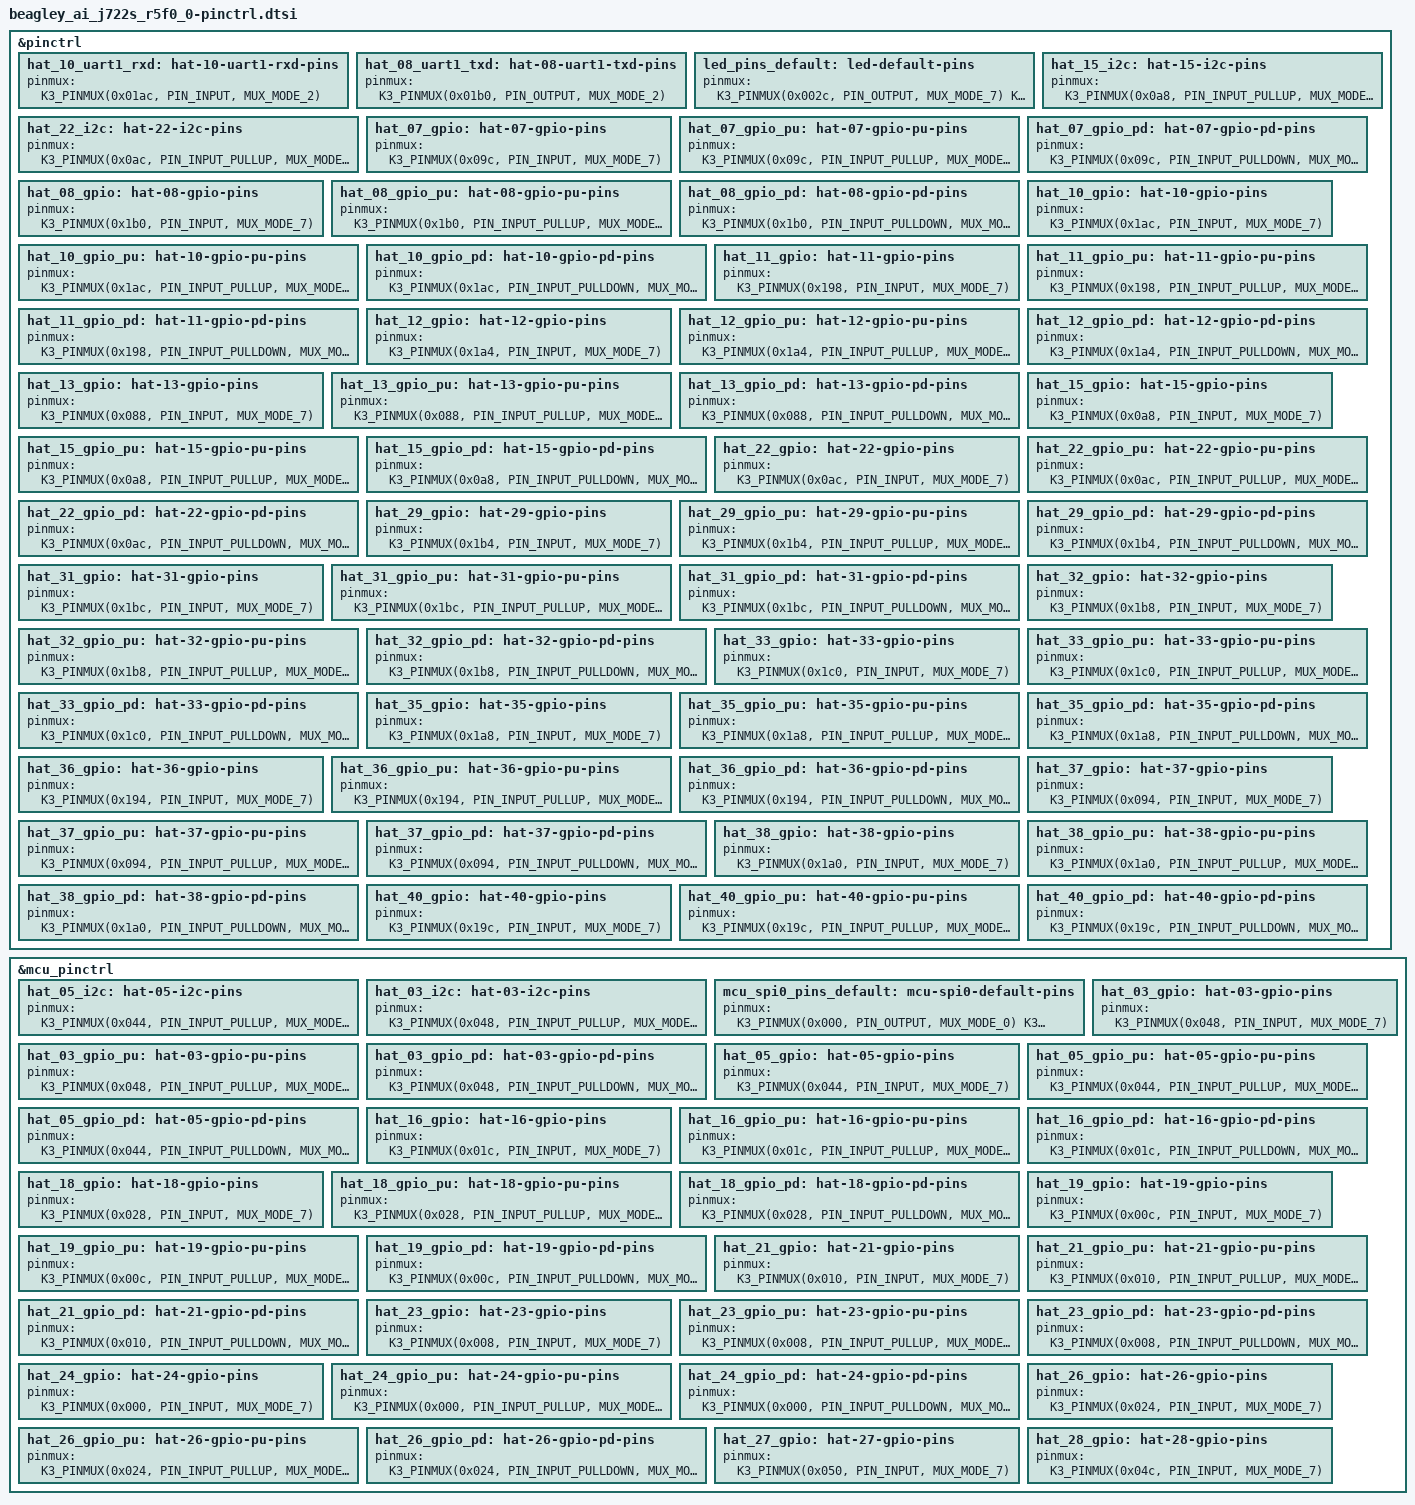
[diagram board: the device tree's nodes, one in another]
/*
 * Copyright (c) 2024 Texas Instruments Incorporated
 *	Andrew Davis <afd@ti.com>
 *
 * SPDX-License-Identifier: Apache-2.0
 */

#include <zephyr/dt-bindings/pinctrl/ti-k3-pinctrl.h>

&pinctrl {
	hat_10_uart1_rxd: hat-10-uart1-rxd-pins {
		/* HAT pin 10, GPIO15, UART RX */
		pinmux = <K3_PINMUX(0x01ac, PIN_INPUT, MUX_MODE_2)>;
	};

	hat_08_uart1_txd: hat-08-uart1-txd-pins {
		/* HAT pin 8, GPIO14, UART TX */
		pinmux = <K3_PINMUX(0x01b0, PIN_OUTPUT, MUX_MODE_2)>;
	};

	led_pins_default: led-default-pins {
		pinmux = <
			  /* (K26) OSPI0_CSn0.GPIO0_11 */
			  K3_PINMUX(0x002c, PIN_OUTPUT, MUX_MODE_7)
			  /* (K23) OSPI0_CSn1.GPIO0_12 */
			  K3_PINMUX(0x0030, PIN_OUTPUT, MUX_MODE_7)>;
	};

	/* Optional HAT I2C4 (https://pinout.beagleboard.io/pinout/i2c) */
	hat_15_i2c: hat-15-i2c-pins {
		/* HAT pin 15, GPIO22, I2C4 clock */
		pinmux = <K3_PINMUX(0x0a8, PIN_INPUT_PULLUP, MUX_MODE_1)>;
	};

	hat_22_i2c: hat-22-i2c-pins {
		/* HAT pin 22, GPIO25, I2C4 data */
		pinmux = <K3_PINMUX(0x0ac, PIN_INPUT_PULLUP, MUX_MODE_1)>;
	};

	hat_07_gpio: hat-07-gpio-pins {
		/* (W26) GPMC0_WAIT1.GPIO0_38 */
		pinmux = <K3_PINMUX(0x09c, PIN_INPUT, MUX_MODE_7)>;
	};

	hat_07_gpio_pu: hat-07-gpio-pu-pins {
		/* (W26) GPMC0_WAIT1.GPIO0_38 */
		pinmux = <K3_PINMUX(0x09c, PIN_INPUT_PULLUP, MUX_MODE_7)>;
	};

	hat_07_gpio_pd: hat-07-gpio-pd-pins {
		/* (W26) GPMC0_WAIT1.GPIO0_38 */
		pinmux = <K3_PINMUX(0x09c, PIN_INPUT_PULLDOWN, MUX_MODE_7)>;
	};

	hat_08_gpio: hat-08-gpio-pins {
		/* (F24) MCASP0_ACLKR.GPIO1_14 */
		pinmux = <K3_PINMUX(0x1b0, PIN_INPUT, MUX_MODE_7)>;
	};

	hat_08_gpio_pu: hat-08-gpio-pu-pins {
		/* (F24) MCASP0_ACLKR.GPIO1_14 */
		pinmux = <K3_PINMUX(0x1b0, PIN_INPUT_PULLUP, MUX_MODE_7)>;
	};

	hat_08_gpio_pd: hat-08-gpio-pd-pins {
		/* (F24) MCASP0_ACLKR.GPIO1_14 */
		pinmux = <K3_PINMUX(0x1b0, PIN_INPUT_PULLDOWN, MUX_MODE_7)>;
	};

	hat_10_gpio: hat-10-gpio-pins {
		/* (C27) MCASP0_AFSR.GPIO1_13 */
		pinmux = <K3_PINMUX(0x1ac, PIN_INPUT, MUX_MODE_7)>;
	};

	hat_10_gpio_pu: hat-10-gpio-pu-pins {
		/* (C27) MCASP0_AFSR.GPIO1_13 */
		pinmux = <K3_PINMUX(0x1ac, PIN_INPUT_PULLUP, MUX_MODE_7)>;
	};

	hat_10_gpio_pd: hat-10-gpio-pd-pins {
		/* (C27) MCASP0_AFSR.GPIO1_13 */
		pinmux = <K3_PINMUX(0x1ac, PIN_INPUT_PULLDOWN, MUX_MODE_7)>;
	};

	hat_11_gpio: hat-11-gpio-pins {
		/* (A26) MCASP0_AXR2.GPIO1_8 */
		pinmux = <K3_PINMUX(0x198, PIN_INPUT, MUX_MODE_7)>;
	};

	hat_11_gpio_pu: hat-11-gpio-pu-pins {
		/* (A26) MCASP0_AXR2.GPIO1_8 */
		pinmux = <K3_PINMUX(0x198, PIN_INPUT_PULLUP, MUX_MODE_7)>;
	};

	hat_11_gpio_pd: hat-11-gpio-pd-pins {
		/* (A26) MCASP0_AXR2.GPIO1_8 */
		pinmux = <K3_PINMUX(0x198, PIN_INPUT_PULLDOWN, MUX_MODE_7)>;
	};

	hat_12_gpio: hat-12-gpio-pins {
		/* (D25) MCASP0_ACLKX.GPIO1_11 */
		pinmux = <K3_PINMUX(0x1a4, PIN_INPUT, MUX_MODE_7)>;
	};

	hat_12_gpio_pu: hat-12-gpio-pu-pins {
		/* (D25) MCASP0_ACLKX.GPIO1_11 */
		pinmux = <K3_PINMUX(0x1a4, PIN_INPUT_PULLUP, MUX_MODE_7)>;
	};

	hat_12_gpio_pd: hat-12-gpio-pd-pins {
		/* (D25) MCASP0_ACLKX.GPIO1_11 */
		pinmux = <K3_PINMUX(0x1a4, PIN_INPUT_PULLDOWN, MUX_MODE_7)>;
	};

	hat_13_gpio: hat-13-gpio-pins {
		/* (N22) GPMC0_OEn_REn.GPIO0_33 */
		pinmux = <K3_PINMUX(0x088, PIN_INPUT, MUX_MODE_7)>;
	};

	hat_13_gpio_pu: hat-13-gpio-pu-pins {
		/* (N22) GPMC0_OEn_REn.GPIO0_33 */
		pinmux = <K3_PINMUX(0x088, PIN_INPUT_PULLUP, MUX_MODE_7)>;
	};

	hat_13_gpio_pd: hat-13-gpio-pd-pins {
		/* (N22) GPMC0_OEn_REn.GPIO0_33 */
		pinmux = <K3_PINMUX(0x088, PIN_INPUT_PULLDOWN, MUX_MODE_7)>;
	};

	hat_15_gpio: hat-15-gpio-pins {
		/* (R27) GPMC0_CSn0.GPIO0_41 */
		pinmux = <K3_PINMUX(0x0a8, PIN_INPUT, MUX_MODE_7)>;
	};

	hat_15_gpio_pu: hat-15-gpio-pu-pins {
		/* (R27) GPMC0_CSn0.GPIO0_41 */
		pinmux = <K3_PINMUX(0x0a8, PIN_INPUT_PULLUP, MUX_MODE_7)>;
	};

	hat_15_gpio_pd: hat-15-gpio-pd-pins {
		/* (R27) GPMC0_CSn0.GPIO0_41 */
		pinmux = <K3_PINMUX(0x0a8, PIN_INPUT_PULLDOWN, MUX_MODE_7)>;
	};

	hat_22_gpio: hat-22-gpio-pins {
		/* (P21) GPMC0_CSn1.GPIO0_42 */
		pinmux = <K3_PINMUX(0x0ac, PIN_INPUT, MUX_MODE_7)>;
	};

	hat_22_gpio_pu: hat-22-gpio-pu-pins {
		/* (P21) GPMC0_CSn1.GPIO0_42 */
		pinmux = <K3_PINMUX(0x0ac, PIN_INPUT_PULLUP, MUX_MODE_7)>;
	};

	hat_22_gpio_pd: hat-22-gpio-pd-pins {
		/* (P21) GPMC0_CSn1.GPIO0_42 */
		pinmux = <K3_PINMUX(0x0ac, PIN_INPUT_PULLDOWN, MUX_MODE_7)>;
	};

	hat_29_gpio: hat-29-gpio-pins {
		/* (B20) SPI0_CS0.GPIO1_15 */
		pinmux = <K3_PINMUX(0x1b4, PIN_INPUT, MUX_MODE_7)>;
	};

	hat_29_gpio_pu: hat-29-gpio-pu-pins {
		/* (B20) SPI0_CS0.GPIO1_15 */
		pinmux = <K3_PINMUX(0x1b4, PIN_INPUT_PULLUP, MUX_MODE_7)>;
	};

	hat_29_gpio_pd: hat-29-gpio-pd-pins {
		/* (B20) SPI0_CS0.GPIO1_15 */
		pinmux = <K3_PINMUX(0x1b4, PIN_INPUT_PULLDOWN, MUX_MODE_7)>;
	};

	hat_31_gpio: hat-31-gpio-pins {
		/* (D20) SPI0_CLK.GPIO1_17 */
		pinmux = <K3_PINMUX(0x1bc, PIN_INPUT, MUX_MODE_7)>;
	};

	hat_31_gpio_pu: hat-31-gpio-pu-pins {
		/* (D20) SPI0_CLK.GPIO1_17 */
		pinmux = <K3_PINMUX(0x1bc, PIN_INPUT_PULLUP, MUX_MODE_7)>;
	};

	hat_31_gpio_pd: hat-31-gpio-pd-pins {
		/* (D20) SPI0_CLK.GPIO1_17 */
		pinmux = <K3_PINMUX(0x1bc, PIN_INPUT_PULLDOWN, MUX_MODE_7)>;
	};

	hat_32_gpio: hat-32-gpio-pins {
		/* (C20) SPI0_CS1.GPIO1_16 */
		pinmux = <K3_PINMUX(0x1b8, PIN_INPUT, MUX_MODE_7)>;
	};

	hat_32_gpio_pu: hat-32-gpio-pu-pins {
		/* (C20) SPI0_CS1.GPIO1_16 */
		pinmux = <K3_PINMUX(0x1b8, PIN_INPUT_PULLUP, MUX_MODE_7)>;
	};

	hat_32_gpio_pd: hat-32-gpio-pd-pins {
		/* (C20) SPI0_CS1.GPIO1_16 */
		pinmux = <K3_PINMUX(0x1b8, PIN_INPUT_PULLDOWN, MUX_MODE_7)>;
	};

	hat_33_gpio: hat-33-gpio-pins {
		/* (E19) SPI0_D0.GPIO1_18 */
		pinmux = <K3_PINMUX(0x1c0, PIN_INPUT, MUX_MODE_7)>;
	};

	hat_33_gpio_pu: hat-33-gpio-pu-pins {
		/* (E19) SPI0_D0.GPIO1_18 */
		pinmux = <K3_PINMUX(0x1c0, PIN_INPUT_PULLUP, MUX_MODE_7)>;
	};

	hat_33_gpio_pd: hat-33-gpio-pd-pins {
		/* (E19) SPI0_D0.GPIO1_18 */
		pinmux = <K3_PINMUX(0x1c0, PIN_INPUT_PULLDOWN, MUX_MODE_7)>;
	};

	hat_35_gpio: hat-35-gpio-pins {
		/* (C26) MCASP0_AFSX.GPIO1_12 */
		pinmux = <K3_PINMUX(0x1a8, PIN_INPUT, MUX_MODE_7)>;
	};

	hat_35_gpio_pu: hat-35-gpio-pu-pins {
		/* (C26) MCASP0_AFSX.GPIO1_12 */
		pinmux = <K3_PINMUX(0x1a8, PIN_INPUT_PULLUP, MUX_MODE_7)>;
	};

	hat_35_gpio_pd: hat-35-gpio-pd-pins {
		/* (C26) MCASP0_AFSX.GPIO1_12 */
		pinmux = <K3_PINMUX(0x1a8, PIN_INPUT_PULLDOWN, MUX_MODE_7)>;
	};

	hat_36_gpio: hat-36-gpio-pins {
		/* (A25) MCASP0_AXR3.GPIO1_7 */
		pinmux = <K3_PINMUX(0x194, PIN_INPUT, MUX_MODE_7)>;
	};

	hat_36_gpio_pu: hat-36-gpio-pu-pins {
		/* (A25) MCASP0_AXR3.GPIO1_7 */
		pinmux = <K3_PINMUX(0x194, PIN_INPUT_PULLUP, MUX_MODE_7)>;
	};

	hat_36_gpio_pd: hat-36-gpio-pd-pins {
		/* (A25) MCASP0_AXR3.GPIO1_7 */
		pinmux = <K3_PINMUX(0x194, PIN_INPUT_PULLDOWN, MUX_MODE_7)>;
	};

	hat_37_gpio: hat-37-gpio-pins {
		/* (P26) GPMC0_BE1n.GPIO0_36 */
		pinmux = <K3_PINMUX(0x094, PIN_INPUT, MUX_MODE_7)>;
	};

	hat_37_gpio_pu: hat-37-gpio-pu-pins {
		/* (P26) GPMC0_BE1n.GPIO0_36 */
		pinmux = <K3_PINMUX(0x094, PIN_INPUT_PULLUP, MUX_MODE_7)>;
	};

	hat_37_gpio_pd: hat-37-gpio-pd-pins {
		/* (P26) GPMC0_BE1n.GPIO0_36 */
		pinmux = <K3_PINMUX(0x094, PIN_INPUT_PULLDOWN, MUX_MODE_7)>;
	};

	hat_38_gpio: hat-38-gpio-pins {
		/* (F23) MCASP0_AXR0.GPIO1_10 */
		pinmux = <K3_PINMUX(0x1a0, PIN_INPUT, MUX_MODE_7)>;
	};

	hat_38_gpio_pu: hat-38-gpio-pu-pins {
		/* (F23) MCASP0_AXR0.GPIO1_10 */
		pinmux = <K3_PINMUX(0x1a0, PIN_INPUT_PULLUP, MUX_MODE_7)>;
	};

	hat_38_gpio_pd: hat-38-gpio-pd-pins {
		/* (F23) MCASP0_AXR0.GPIO1_10 */
		pinmux = <K3_PINMUX(0x1a0, PIN_INPUT_PULLDOWN, MUX_MODE_7)>;
	};

	hat_40_gpio: hat-40-gpio-pins {
		/* (B25) MCASP0_AXR1.GPIO1_9 */
		pinmux = <K3_PINMUX(0x19c, PIN_INPUT, MUX_MODE_7)>;
	};

	hat_40_gpio_pu: hat-40-gpio-pu-pins {
		/* (B25) MCASP0_AXR1.GPIO1_9 */
		pinmux = <K3_PINMUX(0x19c, PIN_INPUT_PULLUP, MUX_MODE_7)>;
	};

	hat_40_gpio_pd: hat-40-gpio-pd-pins {
		/* (B25) MCASP0_AXR1.GPIO1_9 */
		pinmux = <K3_PINMUX(0x19c, PIN_INPUT_PULLDOWN, MUX_MODE_7)>;
	};
};

&mcu_pinctrl {
	/*
	 * Primary HAT I2C (pinout name: I2C1, SoC: MCU_I2C0).
	 * https://pinout.beagleboard.io/pinout/i2c
	 */
	hat_05_i2c: hat-05-i2c-pins {
		/* HAT pin 5, GPIO3, I2C1 clock */
		pinmux = <K3_PINMUX(0x044, PIN_INPUT_PULLUP, MUX_MODE_0)>;
	};

	hat_03_i2c: hat-03-i2c-pins {
		/* HAT pin 3, GPIO2, I2C1 data */
		pinmux = <K3_PINMUX(0x048, PIN_INPUT_PULLUP, MUX_MODE_0)>;
	};

	mcu_spi0_pins_default: mcu-spi0-default-pins {
		pinmux = <
			  /* HAT pin 24, GPIO8, SPI0 CE0 */
			  K3_PINMUX(0x000, PIN_OUTPUT, MUX_MODE_0)
			  /* HAT pin 23, GPIO11, SPI0 SCLK */
			  K3_PINMUX(0x008, PIN_OUTPUT, MUX_MODE_0)
			  /* HAT pin 19, GPIO10, SPI0 MOSI */
			  K3_PINMUX(0x00c, PIN_OUTPUT, MUX_MODE_0)
			  /* HAT pin 21, GPIO9, SPI0 MISO */
			  K3_PINMUX(0x010, PIN_INPUT, MUX_MODE_0)>;
	};

	hat_03_gpio: hat-03-gpio-pins {
		/* HAT pin 3, GPIO2 */
		pinmux = <K3_PINMUX(0x048, PIN_INPUT, MUX_MODE_7)>;
	};

	hat_03_gpio_pu: hat-03-gpio-pu-pins {
		pinmux = <K3_PINMUX(0x048, PIN_INPUT_PULLUP, MUX_MODE_7)>;
	};

	hat_03_gpio_pd: hat-03-gpio-pd-pins {
		pinmux = <K3_PINMUX(0x048, PIN_INPUT_PULLDOWN, MUX_MODE_7)>;
	};

	hat_05_gpio: hat-05-gpio-pins {
		/* HAT pin 5, GPIO3 */
		pinmux = <K3_PINMUX(0x044, PIN_INPUT, MUX_MODE_7)>;
	};

	hat_05_gpio_pu: hat-05-gpio-pu-pins {
		pinmux = <K3_PINMUX(0x044, PIN_INPUT_PULLUP, MUX_MODE_7)>;
	};

	hat_05_gpio_pd: hat-05-gpio-pd-pins {
		pinmux = <K3_PINMUX(0x044, PIN_INPUT_PULLDOWN, MUX_MODE_7)>;
	};

	hat_16_gpio: hat-16-gpio-pins {
		pinmux = <K3_PINMUX(0x01c, PIN_INPUT, MUX_MODE_7)>;
	};

	hat_16_gpio_pu: hat-16-gpio-pu-pins {
		pinmux = <K3_PINMUX(0x01c, PIN_INPUT_PULLUP, MUX_MODE_7)>;
	};

	hat_16_gpio_pd: hat-16-gpio-pd-pins {
		pinmux = <K3_PINMUX(0x01c, PIN_INPUT_PULLDOWN, MUX_MODE_7)>;
	};

	hat_18_gpio: hat-18-gpio-pins {
		pinmux = <K3_PINMUX(0x028, PIN_INPUT, MUX_MODE_7)>;
	};

	hat_18_gpio_pu: hat-18-gpio-pu-pins {
		pinmux = <K3_PINMUX(0x028, PIN_INPUT_PULLUP, MUX_MODE_7)>;
	};

	hat_18_gpio_pd: hat-18-gpio-pd-pins {
		pinmux = <K3_PINMUX(0x028, PIN_INPUT_PULLDOWN, MUX_MODE_7)>;
	};

	hat_19_gpio: hat-19-gpio-pins {
		/* HAT pin 19, GPIO10 */
		pinmux = <K3_PINMUX(0x00c, PIN_INPUT, MUX_MODE_7)>;
	};

	hat_19_gpio_pu: hat-19-gpio-pu-pins {
		pinmux = <K3_PINMUX(0x00c, PIN_INPUT_PULLUP, MUX_MODE_7)>;
	};

	hat_19_gpio_pd: hat-19-gpio-pd-pins {
		pinmux = <K3_PINMUX(0x00c, PIN_INPUT_PULLDOWN, MUX_MODE_7)>;
	};

	hat_21_gpio: hat-21-gpio-pins {
		/* HAT pin 21, GPIO9 */
		pinmux = <K3_PINMUX(0x010, PIN_INPUT, MUX_MODE_7)>;
	};

	hat_21_gpio_pu: hat-21-gpio-pu-pins {
		pinmux = <K3_PINMUX(0x010, PIN_INPUT_PULLUP, MUX_MODE_7)>;
	};

	hat_21_gpio_pd: hat-21-gpio-pd-pins {
		pinmux = <K3_PINMUX(0x010, PIN_INPUT_PULLDOWN, MUX_MODE_7)>;
	};

	hat_23_gpio: hat-23-gpio-pins {
		/* HAT pin 23, GPIO11 */
		pinmux = <K3_PINMUX(0x008, PIN_INPUT, MUX_MODE_7)>;
	};

	hat_23_gpio_pu: hat-23-gpio-pu-pins {
		pinmux = <K3_PINMUX(0x008, PIN_INPUT_PULLUP, MUX_MODE_7)>;
	};

	hat_23_gpio_pd: hat-23-gpio-pd-pins {
		pinmux = <K3_PINMUX(0x008, PIN_INPUT_PULLDOWN, MUX_MODE_7)>;
	};

	hat_24_gpio: hat-24-gpio-pins {
		/* HAT pin 24, GPIO8 */
		pinmux = <K3_PINMUX(0x000, PIN_INPUT, MUX_MODE_7)>;
	};

	hat_24_gpio_pu: hat-24-gpio-pu-pins {
		pinmux = <K3_PINMUX(0x000, PIN_INPUT_PULLUP, MUX_MODE_7)>;
	};

	hat_24_gpio_pd: hat-24-gpio-pd-pins {
		pinmux = <K3_PINMUX(0x000, PIN_INPUT_PULLDOWN, MUX_MODE_7)>;
	};

	hat_26_gpio: hat-26-gpio-pins {
		pinmux = <K3_PINMUX(0x024, PIN_INPUT, MUX_MODE_7)>;
	};

	hat_26_gpio_pu: hat-26-gpio-pu-pins {
		pinmux = <K3_PINMUX(0x024, PIN_INPUT_PULLUP, MUX_MODE_7)>;
	};

	hat_26_gpio_pd: hat-26-gpio-pd-pins {
		pinmux = <K3_PINMUX(0x024, PIN_INPUT_PULLDOWN, MUX_MODE_7)>;
	};

	hat_27_gpio: hat-27-gpio-pins {
		/* HAT pin 27, GPIO0, I2C0 data (PMIC bus; avoid) */
		pinmux = <K3_PINMUX(0x050, PIN_INPUT, MUX_MODE_7)>;
	};

	hat_28_gpio: hat-28-gpio-pins {
		/* HAT pin 28, GPIO1, I2C0 clock (PMIC bus; avoid) */
		pinmux = <K3_PINMUX(0x04c, PIN_INPUT, MUX_MODE_7)>;
	};
};
